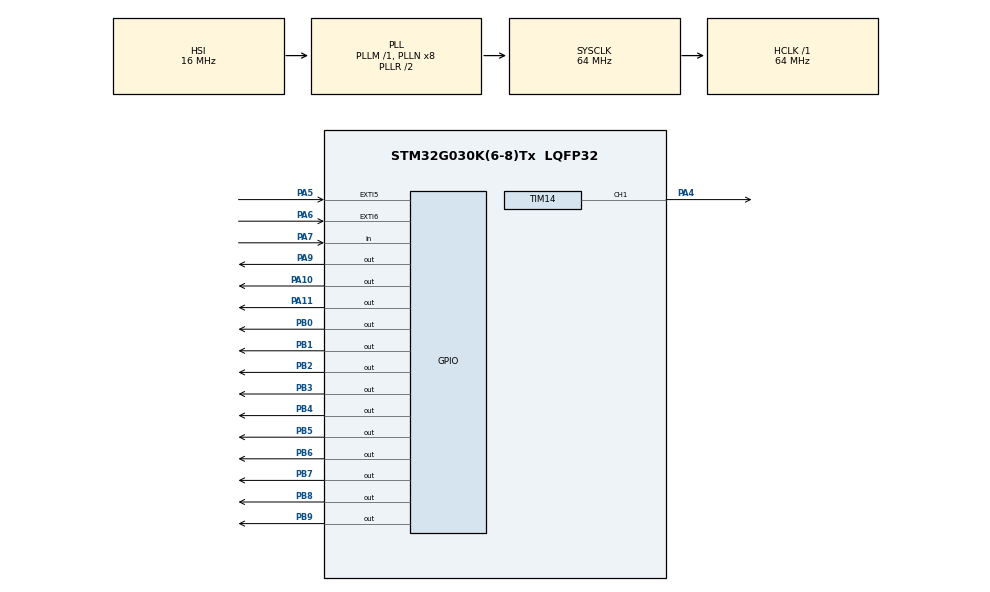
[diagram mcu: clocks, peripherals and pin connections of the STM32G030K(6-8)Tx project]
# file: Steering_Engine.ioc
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Mcu.Family=STM32G0
Mcu.Name=STM32G030K(6-8)Tx
Mcu.Package=LQFP32
NVIC.EXTI4_15_IRQn=true\:0\:0\:false\:false\:true\:true\:true\:true
NVIC.TIM1_BRK_UP_TRG_COM_IRQn=true\:1\:0\:true\:false\:true\:true\:true\:true
PA10.PinState=GPIO_PIN_SET
PA10.Signal=GPIO_Output
PA11\ [PA9].PinState=GPIO_PIN_SET
PA11\ [PA9].Signal=GPIO_Output
PA13.Mode=Serial_Wire
PA13.Signal=SYS_SWDIO
PA14-BOOT0.Mode=Serial_Wire
PA14-BOOT0.Signal=SYS_SWCLK
PA4.Signal=S_TIM14_CH1
PA5.GPIO_ModeDefaultEXTI=GPIO_MODE_IT_FALLING
PA5.GPIO_PuPd=GPIO_PULLUP
PA5.Signal=GPXTI5
PA6.GPIO_ModeDefaultEXTI=GPIO_MODE_IT_RISING
PA6.GPIO_PuPd=GPIO_PULLUP
PA6.Signal=GPXTI6
PA7.GPIO_PuPd=GPIO_PULLUP
PA7.Signal=GPIO_Input
PA9.PinState=GPIO_PIN_SET
PA9.Signal=GPIO_Output
PB0.PinState=GPIO_PIN_RESET
PB0.Signal=GPIO_Output
PB1.PinState=GPIO_PIN_RESET
PB1.Signal=GPIO_Output
PB2.PinState=GPIO_PIN_RESET
PB2.Signal=GPIO_Output
PB3.PinState=GPIO_PIN_RESET
PB3.Signal=GPIO_Output
PB4.PinState=GPIO_PIN_RESET
PB4.Signal=GPIO_Output
PB5.PinState=GPIO_PIN_RESET
PB5.Signal=GPIO_Output
PB6.PinState=GPIO_PIN_RESET
PB6.Signal=GPIO_Output
PB7.PinState=GPIO_PIN_SET
PB7.Signal=GPIO_Output
PB8.PinState=GPIO_PIN_SET
PB8.Signal=GPIO_Output
PB9.PinState=GPIO_PIN_SET
PB9.Signal=GPIO_Output
ProjectManager.HeapSize=0x200
ProjectManager.StackSize=0x400
ProjectManager.TargetToolchain=CMake
RCC.ADCFreq_Value=64000000
RCC.AHBFreq_Value=64000000
RCC.CortexFreq_Value=64000000
RCC.EXTERNAL_CLOCK_VALUE=12288000
RCC.HCLKFreq_Value=64000000
RCC.HSE_VALUE=8000000
RCC.HSI_VALUE=16000000
RCC.LSE_VALUE=32768
RCC.SYSCLKFreq_VALUE=64000000
RCC.SYSCLKSource=RCC_SYSCLKSOURCE_PLLCLK
RCC.VCOOutputFreq_Value=128000000
SH.S_TIM14_CH1.0=TIM14_CH1,PWM Generation1 CH1
TIM1.Period=999
TIM1.Prescaler=63
TIM14.Channel=TIM_CHANNEL_1
TIM14.Period=19999
TIM14.Prescaler=63
TIM14.Pulse=500
VP_TIM14_VS_ClockSourceINT.Mode=Enable_Timer
VP_TIM1_VS_ClockSourceINT.Mode=Internal
board=custom

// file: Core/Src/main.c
/* USER CODE BEGIN Header */
/**
  ******************************************************************************
  * @file           : main.c
  * @brief          : Main program body
  ******************************************************************************
  * @attention
  *
  * Copyright (c) 2026 STMicroelectronics.
  * All rights reserved.
  *
  * This software is licensed under terms that can be found in the LICENSE file
  * in the root directory of this software component.
  * If no LICENSE file comes with this software, it is provided AS-IS.
  *
  ******************************************************************************
  */
/* USER CODE END Header */
#include "main.h"
#include "tim.h"
#include "gpio.h"

/* USER CODE BEGIN Includes */
#include "global.h"
/* USER CODE END Includes */

void SystemClock_Config(void);

int main(void)
{

  /* MCU Configuration--------------------------------------------------------*/

  /* Reset of all peripherals, Initializes the Flash interface and the Systick. */
  HAL_Init();

  /* Configure the system clock */
  SystemClock_Config();

  /* Initialize all configured peripherals */
  MX_GPIO_Init();
  MX_TIM14_Init();
  MX_TIM1_Init();
  /* USER CODE BEGIN 2 */
  //TIM1
  HAL_TIM_Base_Start_IT(&htim1);
  //servo
  HAL_TIM_PWM_Start(&htim14, TIM_CHANNEL_1);
  /* USER CODE END 2 */

  /* Infinite loop */
  /* USER CODE BEGIN WHILE */
  while (1)
  {
      Mode_Process();
  }
    /* USER CODE END WHILE */

}

void SystemClock_Config(void)
{
  RCC_OscInitTypeDef RCC_OscInitStruct = {0};
  RCC_ClkInitTypeDef RCC_ClkInitStruct = {0};

  /** Configure the main internal regulator output voltage
  */
  HAL_PWREx_ControlVoltageScaling(PWR_REGULATOR_VOLTAGE_SCALE1);

  /** Initializes the RCC Oscillators according to the specified parameters
  * in the RCC_OscInitTypeDef structure.
  */
  RCC_OscInitStruct.OscillatorType = RCC_OSCILLATORTYPE_HSI;
  RCC_OscInitStruct.HSIState = RCC_HSI_ON;
  RCC_OscInitStruct.HSIDiv = RCC_HSI_DIV1;
  RCC_OscInitStruct.HSICalibrationValue = RCC_HSICALIBRATION_DEFAULT;
  RCC_OscInitStruct.PLL.PLLState = RCC_PLL_ON;
  RCC_OscInitStruct.PLL.PLLSource = RCC_PLLSOURCE_HSI;
  RCC_OscInitStruct.PLL.PLLM = RCC_PLLM_DIV1;
  RCC_OscInitStruct.PLL.PLLN = 8;
  RCC_OscInitStruct.PLL.PLLP = RCC_PLLP_DIV2;
  RCC_OscInitStruct.PLL.PLLR = RCC_PLLR_DIV2;
  if (HAL_RCC_OscConfig(&RCC_OscInitStruct) != HAL_OK)
  {
    Error_Handler();
  }

  /** Initializes the CPU, AHB and APB buses clocks
  */
  RCC_ClkInitStruct.ClockType = RCC_CLOCKTYPE_HCLK|RCC_CLOCKTYPE_SYSCLK
                              |RCC_CLOCKTYPE_PCLK1;
  RCC_ClkInitStruct.SYSCLKSource = RCC_SYSCLKSOURCE_PLLCLK;
  RCC_ClkInitStruct.AHBCLKDivider = RCC_SYSCLK_DIV1;
  RCC_ClkInitStruct.APB1CLKDivider = RCC_HCLK_DIV1;

  if (HAL_RCC_ClockConfig(&RCC_ClkInitStruct, FLASH_LATENCY_2) != HAL_OK)
  {
    Error_Handler();
  }
}

void Error_Handler(void)
{
  __disable_irq();
  while (1)
  {
  }
}
